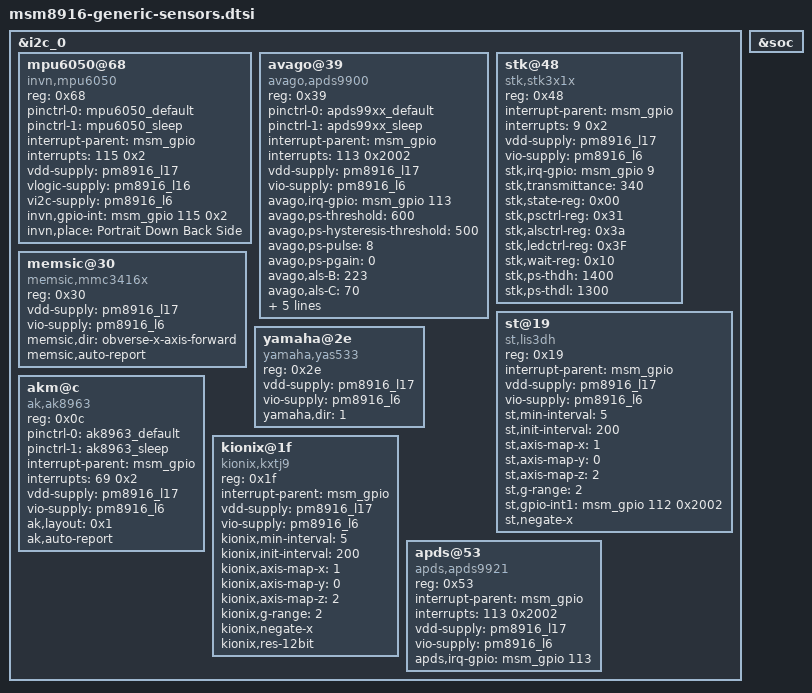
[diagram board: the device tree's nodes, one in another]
#include "msm8916.dtsi"
#include "msm8916-pinctrl.dtsi"

&i2c_0 { /* BLSP1 QUP2 */
	mpu6050@68 { /* Gyroscope and accelerometer sensor combo */
			compatible = "invn,mpu6050";
			reg = <0x68>;
			pinctrl-names = "mpu_default","mpu_sleep";
			pinctrl-0 = <&mpu6050_default>;
			pinctrl-1 = <&mpu6050_sleep>;
			interrupt-parent = <&msm_gpio>;
			interrupts = <115 0x2>;
			vdd-supply = <&pm8916_l17>;
			vlogic-supply = <&pm8916_l16>;
			vi2c-supply = <&pm8916_l6>;
			invn,gpio-int = <&msm_gpio 115 0x2>;
			invn,place = "Portrait Down Back Side";
		};

		avago@39 { /* Ambient light and proximity sensor */
			compatible = "avago,apds9900";
			reg = <0x39>;
			pinctrl-names = "default","sleep";
			pinctrl-0 = <&apds99xx_default>;
			pinctrl-1 = <&apds99xx_sleep>;
			interrupt-parent = <&msm_gpio>;
			interrupts = <113 0x2002>;
			vdd-supply = <&pm8916_l17>;
			vio-supply = <&pm8916_l6>;
			avago,irq-gpio = <&msm_gpio 113 0x2002>;
			avago,ps-threshold = <600>;
			avago,ps-hysteresis-threshold = <500>;
			avago,ps-pulse = <8>;
			avago,ps-pgain = <0>;
			avago,als-B = <223>;
			avago,als-C = <70>;
			avago,als-D = <142>;
			avago,ga-value = <48>;
			
			panel_id0 = <&msm_gpio 109 0x00>;
			panel_id1 = <&msm_gpio 114 0x00>;
			panel_id2 = <&msm_gpio 119 0x00>;	
		};


		/* LiuPing@Phone.BSP.Sensor, 2014/07/19, add for alsps:stk3x1x */
		stk@48 {
			compatible = "stk,stk3x1x";
			reg = <0x48>;
			interrupt-parent = <&msm_gpio>;
			interrupts = <9 0x2>;
			vdd-supply = <&pm8916_l17>;
			vio-supply = <&pm8916_l6>;
			stk,irq-gpio = <&msm_gpio 9 0x02>;
			stk,transmittance = <340>;
			stk,state-reg = <0x00>;
			stk,psctrl-reg = <0x31>;
			stk,alsctrl-reg = <0x3a>;
			stk,ledctrl-reg = <0x3F>;
			stk,wait-reg = <0x10>;
			stk,ps-thdh = <1400>;
			stk,ps-thdl = <1300>;
			//stk,use-fir; 
		};

		/* LiuPing@Phone.BSP.Sensor, 2014/09/02, add for gsensor:lis3dh */
		st@19 { /* Accelerometer sensor */
			compatible = "st,lis3dh";
			reg = <0x19>;
			interrupt-parent = <&msm_gpio>;
			vdd-supply = <&pm8916_l17>;
			vio-supply = <&pm8916_l6>;
			st,min-interval = <5>;
			st,init-interval = <200>;
			//#ifndef VENDOR_EDIT xiaohua.tian@EXP.driver modify sensor direction, 2016-01-16
			//st,axis-map-x = <0>;
			//st,axis-map-y = <1>;
			//#else
			st,axis-map-x = <1>;
			st,axis-map-y = <0>;
			//#endif
			st,axis-map-z = <2>;
			st,g-range = <2>;
			st,gpio-int1 = <&msm_gpio 112 0x2002>;
			st,negate-x;
			//st,negate-y;	
			//#ifdef VENDOR_EDIT xiaohua.tian@EXP.driver modify sensor direction, 2016-01-16		
			//st,negate-z;
			//#endif
		};	

		/* LiuPing@Phone.BSP.Sensor, 2014/09/04, add for msensor:mmc3416x */
		memsic@30 { /* Magnetic field sensor */
			compatible = "memsic,mmc3416x";
			reg = <0x30>;
			vdd-supply = <&pm8916_l17>;
			vio-supply = <&pm8916_l6>;
			//#ifndef VENDOR_EDIT xiaohua.tian@EXP.driver modify sensor direction, 2016-01-16
			//memsic,dir = "reverse-x-axis-leftward";
			//#else
			memsic,dir = "obverse-x-axis-forward";
			//#endif
			memsic,auto-report;
		};		

		yamaha@2e { /* Magnetic field sensor */
			compatible = "yamaha,yas533";
			reg = <0x2e>;
			vdd-supply = <&pm8916_l17>;
			vio-supply = <&pm8916_l6>;
			yamaha,dir = <1>;
		};		

		akm@c {
			compatible = "ak,ak8963";
			reg = <0x0c>;
			pinctrl-names = "ak8963_default", "ak8963_sleep";
			pinctrl-0 = <&ak8963_default>;
			pinctrl-1 = <&ak8963_sleep>;
			interrupt-parent = <&msm_gpio>;
			interrupts = <69 0x2>;
			vdd-supply = <&pm8916_l17>;
			vio-supply = <&pm8916_l6>;
			ak,layout = <0x1>;
			ak,auto-report;
		};
		
		kionix@1f { 
			compatible = "kionix,kxtj9";
			reg = <0x1f>;
			interrupt-parent = <&msm_gpio>;
			vdd-supply = <&pm8916_l17>;
			vio-supply = <&pm8916_l6>;
			kionix,min-interval = <5>;
			kionix,init-interval = <200>;
			/*#ifndef VENDOR_EDIT //xiaohua.tian@EXP.Driver modify for gsensor orientation, 2016-07-22*/
			//kionix,axis-map-x = <0>;
			//kionix,axis-map-y = <1>;
			/*#else*/
			kionix,axis-map-x = <1>;
			kionix,axis-map-y = <0>;
			/*#endif*/
			kionix,axis-map-z = <2>;
			kionix,g-range = <2>;
			kionix,negate-x;
			//kionix,negate-y;
			/*#ifdef VENDOR_EDIT //xiaohua.tian@EXP.Driver modify for gsensor orientation, 2016-07-22*/
			//kionix,negate-z;
			/*#endif*/
			kionix,res-12bit; 
		};

		
		apds@53 { 
			compatible = "apds,apds9921";
			reg = <0x53>;
			interrupt-parent = <&msm_gpio>;
			/*#ifndef VENDOR_EDIT //xiaohua.tian@EXP.Driver modify for ps_als sensor, 2016-01-06*/
			//interrupts = <9 0x2>;
			/*#else*/
			interrupts = <113 0x2002>;
			/*#endif*/
			vdd-supply = <&pm8916_l17>;
			vio-supply = <&pm8916_l6>;
			/*#ifndef VENDOR_EDIT //xiaohua.tian@EXP.Driver modify for ps_als sensor, 2016-01-06*/
			//apds,irq-gpio = <&msm_gpio 9 0x02>;
			/*#else*/
			apds,irq-gpio = <&msm_gpio 113 0x2002>;
			/*#endif*/
		};
};

&soc{
/*	uei {
		compatible = "uei";
		uei,power-gpio = <&msm_gpio 115 0x2008>;
	};*/
};
